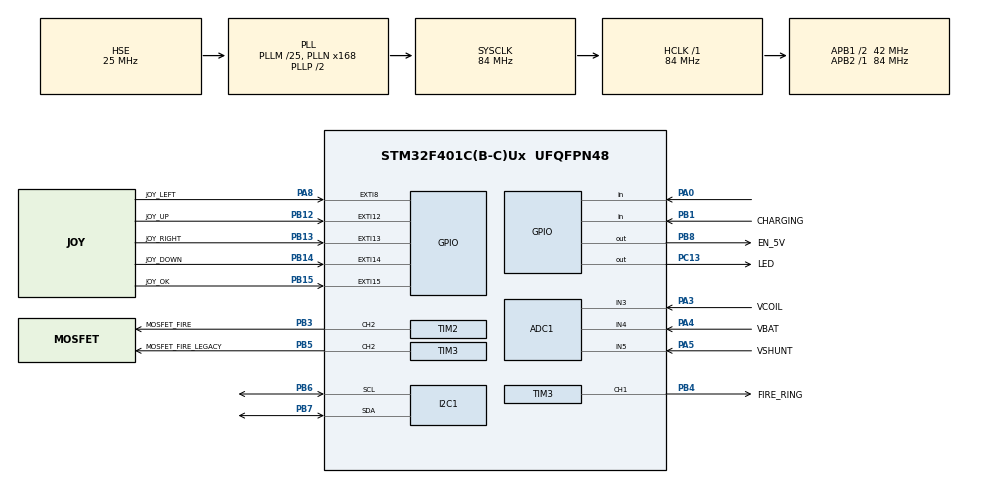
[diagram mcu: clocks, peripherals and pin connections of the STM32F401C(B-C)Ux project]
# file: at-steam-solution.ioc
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ADC1.Channel-0\#ChannelRegularConversion=ADC_CHANNEL_3
ADC1.Channel-1\#ChannelRegularConversion=ADC_CHANNEL_4
ADC1.Channel-2\#ChannelRegularConversion=ADC_CHANNEL_5
ADC1.ContinuousConvMode=ENABLE
ADC1.DMAContinuousRequests=ENABLE
ADC1.NbrOfConversion=3
ADC1.NbrOfConversionFlag=1
ADC1.Rank-0\#ChannelRegularConversion=1
ADC1.Rank-1\#ChannelRegularConversion=2
ADC1.Rank-2\#ChannelRegularConversion=3
ADC1.SamplingTime-0\#ChannelRegularConversion=ADC_SAMPLETIME_480CYCLES
ADC1.SamplingTime-1\#ChannelRegularConversion=ADC_SAMPLETIME_480CYCLES
ADC1.SamplingTime-2\#ChannelRegularConversion=ADC_SAMPLETIME_480CYCLES
ADC1.master=1
Dma.ADC1.0.Direction=DMA_PERIPH_TO_MEMORY
Dma.ADC1.0.FIFOMode=DMA_FIFOMODE_DISABLE
Dma.ADC1.0.Instance=DMA2_Stream0
Dma.ADC1.0.MemDataAlignment=DMA_MDATAALIGN_WORD
Dma.ADC1.0.MemInc=DMA_MINC_ENABLE
Dma.ADC1.0.Mode=DMA_CIRCULAR
Dma.ADC1.0.PeriphDataAlignment=DMA_PDATAALIGN_WORD
Dma.ADC1.0.PeriphInc=DMA_PINC_DISABLE
Dma.ADC1.0.Priority=DMA_PRIORITY_LOW
Dma.Request0=ADC1
I2C1.I2C_Mode=I2C_Fast
Mcu.Family=STM32F4
Mcu.Name=STM32F401C(B-C)Ux
Mcu.Package=UFQFPN48
NVIC.DMA2_Stream0_IRQn=true\:0\:0\:false\:false\:true\:false\:true
NVIC.EXTI15_10_IRQn=true\:0\:0\:false\:false\:true\:true\:true
NVIC.EXTI9_5_IRQn=true\:0\:0\:false\:false\:true\:true\:true
NVIC.PriorityGroup=NVIC_PRIORITYGROUP_4
NVIC.TIM4_IRQn=true\:0\:0\:false\:false\:true\:true\:true
PA0-WKUP.GPIO_PuPd=GPIO_PULLDOWN
PA0-WKUP.Signal=GPIO_Input
PA3.GPIO_Label=VCOIL
PA3.Signal=ADCx_IN3
PA4.GPIO_Label=VBAT
PA4.Signal=ADCx_IN4
PA5.GPIO_Label=VSHUNT
PA5.Signal=ADCx_IN5
PA8.GPIO_Label=JOY_LEFT
PA8.GPIO_ModeDefaultEXTI=GPIO_MODE_IT_RISING_FALLING
PA8.GPIO_PuPd=GPIO_PULLUP
PA8.Signal=GPXTI8
PB1.GPIO_Label=CHARGING
PB1.Signal=GPIO_Input
PB12.GPIO_Label=JOY_UP
PB12.GPIO_ModeDefaultEXTI=GPIO_MODE_IT_RISING_FALLING
PB12.GPIO_PuPd=GPIO_PULLUP
PB12.Signal=GPXTI12
PB13.GPIO_Label=JOY_RIGHT
PB13.GPIO_ModeDefaultEXTI=GPIO_MODE_IT_RISING_FALLING
PB13.GPIO_PuPd=GPIO_PULLUP
PB13.Signal=GPXTI13
PB14.GPIO_Label=JOY_DOWN
PB14.GPIO_ModeDefaultEXTI=GPIO_MODE_IT_RISING_FALLING
PB14.GPIO_PuPd=GPIO_PULLUP
PB14.Signal=GPXTI14
PB15.GPIO_Label=JOY_OK
PB15.GPIO_ModeDefaultEXTI=GPIO_MODE_IT_RISING_FALLING
PB15.GPIO_PuPd=GPIO_PULLUP
PB15.Signal=GPXTI15
PB3.GPIO_Label=MOSFET_FIRE
PB3.GPIO_ModeDefaultPP=GPIO_MODE_AF_OD
PB3.GPIO_Speed=GPIO_SPEED_FREQ_VERY_HIGH
PB3.Signal=S_TIM2_CH2
PB4.GPIO_Label=FIRE_RING
PB4.GPIO_ModeDefaultPP=GPIO_MODE_AF_OD
PB4.GPIO_Speed=GPIO_SPEED_FREQ_VERY_HIGH
PB4.Signal=S_TIM3_CH1
PB5.GPIO_Label=MOSFET_FIRE_LEGACY
PB5.GPIO_ModeDefaultPP=GPIO_MODE_AF_OD
PB5.GPIO_Speed=GPIO_SPEED_FREQ_VERY_HIGH
PB5.Signal=S_TIM3_CH2
PB6.GPIO_Pu=GPIO_PULLUP
PB6.Mode=I2C
PB6.Signal=I2C1_SCL
PB7.GPIO_Pu=GPIO_PULLUP
PB7.Mode=I2C
PB7.Signal=I2C1_SDA
PB8.GPIO_Label=EN_5V
PB8.Signal=GPIO_Output
PC13-ANTI_TAMP.GPIO_Label=LED
PC13-ANTI_TAMP.Signal=GPIO_Output
PC14-OSC32_IN.Mode=LSE-External-Oscillator
PC14-OSC32_IN.Signal=RCC_OSC32_IN
PC15-OSC32_OUT.Mode=LSE-External-Oscillator
PC15-OSC32_OUT.Signal=RCC_OSC32_OUT
PH0\ -\ OSC_IN.Mode=HSE-External-Oscillator
PH0\ -\ OSC_IN.Signal=RCC_OSC_IN
PH1\ -\ OSC_OUT.Mode=HSE-External-Oscillator
PH1\ -\ OSC_OUT.Signal=RCC_OSC_OUT
ProjectManager.HeapSize=0x200
ProjectManager.StackSize=0x400
ProjectManager.TargetToolchain=SW4STM32
RCC.48MHZClocksFreq_Value=42000000
RCC.AHBFreq_Value=84000000
RCC.APB1CLKDivider=RCC_HCLK_DIV2
RCC.APB1Freq_Value=42000000
RCC.APB1TimFreq_Value=84000000
RCC.APB2Freq_Value=84000000
RCC.APB2TimFreq_Value=84000000
RCC.CortexFreq_Value=84000000
RCC.HCLKFreq_Value=84000000
RCC.HSE_VALUE=25000000
RCC.HSI_VALUE=16000000
RCC.PLLM=25
RCC.PLLN=168
RCC.PLLSourceVirtual=RCC_PLLSOURCE_HSE
RCC.RCC_RTC_Clock_Source=RCC_RTCCLKSOURCE_LSE
RCC.RCC_RTC_Clock_SourceVirtual=RCC_RTCCLKSOURCE_LSE
RCC.RCC_RTC_Clock_Source_FROM_HSE=RCC_RTCCLKSOURCE_HSE_DIV25
RCC.SYSCLKFreq_VALUE=84000000
RCC.SYSCLKSource=RCC_SYSCLKSOURCE_PLLCLK
RCC.VCOOutputFreq_Value=168000000
RTC.AsynchPrediv=127
RTC.SynchPrediv=255
SH.ADCx_IN3.0=ADC1_IN3,IN3
SH.ADCx_IN4.0=ADC1_IN4,IN4
SH.ADCx_IN5.0=ADC1_IN5,IN5
SH.S_TIM2_CH2.0=TIM2_CH2,PWM Generation2 CH2
SH.S_TIM3_CH1.0=TIM3_CH1,PWM Generation1 CH1
SH.S_TIM3_CH2.0=TIM3_CH2,PWM Generation2 CH2
TIM2.Channel-PWM\ Generation2\ CH2=TIM_CHANNEL_2
TIM2.Period=10000-1
TIM2.Prescaler=100-1
TIM3.Channel-PWM\ Generation1\ CH1=TIM_CHANNEL_1
TIM3.Channel-PWM\ Generation2\ CH2=TIM_CHANNEL_2
TIM3.Period=10000-1
TIM3.Prescaler=100-1
TIM4.Period=8400-1
TIM4.Prescaler=100-1
VP_CRC_VS_CRC.Mode=CRC_Activate
VP_RTC_VS_RTC_Activate.Mode=RTC_Enabled
VP_RTC_VS_RTC_Calendar.Mode=RTC_Calendar
VP_TIM4_VS_ClockSourceINT.Mode=Internal
board=custom

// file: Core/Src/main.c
/* USER CODE BEGIN Header */
/*
 * Copyright (c) Alex2772, https://github.com/alex2772
 *
 * This program is free software: you can redistribute it and/or modify
 * it under the terms of the GNU General Public License as published by
 * the Free Software Foundation, either version 3 of the License, or
 * (at your option) any later version.
 *
 * This program is distributed in the hope that it will be useful,
 * but WITHOUT ANY WARRANTY; without even the implied warranty of
 * MERCHANTABILITY or FITNESS FOR A PARTICULAR PURPOSE.  See the
 * GNU General Public License for more details.
 *
 * You should have received a copy of the GNU General Public License
 * along with this program.  If not, see <http://www.gnu.org/licenses/>.
 */

/* USER CODE END Header */
#include "main.h"

ADC_HandleTypeDef hadc1;
DMA_HandleTypeDef hdma_adc1;

CRC_HandleTypeDef hcrc;

I2C_HandleTypeDef hi2c1;

RTC_HandleTypeDef hrtc;

TIM_HandleTypeDef htim2;
TIM_HandleTypeDef htim3;
TIM_HandleTypeDef htim4;

void SystemClock_Config(void);
static void MX_GPIO_Init(void);
static void MX_I2C1_Init(void);
static void MX_TIM3_Init(void);
static void MX_DMA_Init(void);
static void MX_ADC1_Init(void);
static void MX_TIM4_Init(void);
static void MX_CRC_Init(void);
static void MX_RTC_Init(void);
static void MX_TIM2_Init(void);

/* USER CODE BEGIN 0 */

extern void app_run();
/* USER CODE END 0 */

int main(void)
{

  /* MCU Configuration--------------------------------------------------------*/

  /* Reset of all peripherals, Initializes the Flash interface and the Systick. */
  HAL_Init();

  /* Configure the system clock */
  SystemClock_Config();

  /* Initialize all configured peripherals */
  MX_GPIO_Init();
  MX_I2C1_Init();
  MX_TIM3_Init();
  MX_DMA_Init();
  MX_ADC1_Init();
  MX_TIM4_Init();
  MX_CRC_Init();
  MX_RTC_Init();
  MX_TIM2_Init();
  /* USER CODE BEGIN 2 */

  HAL_PWR_EnableBkUpAccess();

  /* USER CODE END 2 */

  /* Infinite loop */
  while (1)
  {

    /* USER CODE BEGIN 3 */
    app_run();
  }
  /* USER CODE END 3 */
}

void SystemClock_Config(void)
{
  RCC_OscInitTypeDef RCC_OscInitStruct = {0};
  RCC_ClkInitTypeDef RCC_ClkInitStruct = {0};

  /** Configure the main internal regulator output voltage
  */
  __HAL_RCC_PWR_CLK_ENABLE();
  __HAL_PWR_VOLTAGESCALING_CONFIG(PWR_REGULATOR_VOLTAGE_SCALE2);
  /** Initializes the RCC Oscillators according to the specified parameters
  * in the RCC_OscInitTypeDef structure.
  */
  RCC_OscInitStruct.OscillatorType = RCC_OSCILLATORTYPE_HSE|RCC_OSCILLATORTYPE_LSE;
  RCC_OscInitStruct.HSEState = RCC_HSE_ON;
  RCC_OscInitStruct.LSEState = RCC_LSE_ON;
  RCC_OscInitStruct.PLL.PLLState = RCC_PLL_ON;
  RCC_OscInitStruct.PLL.PLLSource = RCC_PLLSOURCE_HSE;
  RCC_OscInitStruct.PLL.PLLM = 25;
  RCC_OscInitStruct.PLL.PLLN = 168;
  RCC_OscInitStruct.PLL.PLLP = RCC_PLLP_DIV2;
  RCC_OscInitStruct.PLL.PLLQ = 4;
  if (HAL_RCC_OscConfig(&RCC_OscInitStruct) != HAL_OK)
  {
    Error_Handler();
  }
  /** Initializes the CPU, AHB and APB buses clocks
  */
  RCC_ClkInitStruct.ClockType = RCC_CLOCKTYPE_HCLK|RCC_CLOCKTYPE_SYSCLK
                              |RCC_CLOCKTYPE_PCLK1|RCC_CLOCKTYPE_PCLK2;
  RCC_ClkInitStruct.SYSCLKSource = RCC_SYSCLKSOURCE_PLLCLK;
  RCC_ClkInitStruct.AHBCLKDivider = RCC_SYSCLK_DIV1;
  RCC_ClkInitStruct.APB1CLKDivider = RCC_HCLK_DIV2;
  RCC_ClkInitStruct.APB2CLKDivider = RCC_HCLK_DIV1;

  if (HAL_RCC_ClockConfig(&RCC_ClkInitStruct, FLASH_LATENCY_2) != HAL_OK)
  {
    Error_Handler();
  }
}

static void MX_ADC1_Init(void)
{

  ADC_ChannelConfTypeDef sConfig = {0};

  /** Configure the global features of the ADC (Clock, Resolution, Data Alignment and number of conversion)
  */
  hadc1.Instance = ADC1;
  hadc1.Init.ClockPrescaler = ADC_CLOCK_SYNC_PCLK_DIV4;
  hadc1.Init.Resolution = ADC_RESOLUTION_12B;
  hadc1.Init.ScanConvMode = ENABLE;
  hadc1.Init.ContinuousConvMode = ENABLE;
  hadc1.Init.DiscontinuousConvMode = DISABLE;
  hadc1.Init.ExternalTrigConvEdge = ADC_EXTERNALTRIGCONVEDGE_NONE;
  hadc1.Init.ExternalTrigConv = ADC_SOFTWARE_START;
  hadc1.Init.DataAlign = ADC_DATAALIGN_RIGHT;
  hadc1.Init.NbrOfConversion = 3;
  hadc1.Init.DMAContinuousRequests = ENABLE;
  hadc1.Init.EOCSelection = ADC_EOC_SINGLE_CONV;
  if (HAL_ADC_Init(&hadc1) != HAL_OK)
  {
    Error_Handler();
  }
  /** Configure for the selected ADC regular channel its corresponding rank in the sequencer and its sample time.
  */
  sConfig.Channel = ADC_CHANNEL_3;
  sConfig.Rank = 1;
  sConfig.SamplingTime = ADC_SAMPLETIME_480CYCLES;
  if (HAL_ADC_ConfigChannel(&hadc1, &sConfig) != HAL_OK)
  {
    Error_Handler();
  }
  /** Configure for the selected ADC regular channel its corresponding rank in the sequencer and its sample time.
  */
  sConfig.Channel = ADC_CHANNEL_4;
  sConfig.Rank = 2;
  if (HAL_ADC_ConfigChannel(&hadc1, &sConfig) != HAL_OK)
  {
    Error_Handler();
  }
  /** Configure for the selected ADC regular channel its corresponding rank in the sequencer and its sample time.
  */
  sConfig.Channel = ADC_CHANNEL_5;
  sConfig.Rank = 3;
  if (HAL_ADC_ConfigChannel(&hadc1, &sConfig) != HAL_OK)
  {
    Error_Handler();
  }

}

static void MX_CRC_Init(void)
{

  hcrc.Instance = CRC;
  if (HAL_CRC_Init(&hcrc) != HAL_OK)
  {
    Error_Handler();
  }

}

static void MX_I2C1_Init(void)
{

  hi2c1.Instance = I2C1;
  hi2c1.Init.ClockSpeed = 400000;
  hi2c1.Init.DutyCycle = I2C_DUTYCYCLE_2;
  hi2c1.Init.OwnAddress1 = 0;
  hi2c1.Init.AddressingMode = I2C_ADDRESSINGMODE_7BIT;
  hi2c1.Init.DualAddressMode = I2C_DUALADDRESS_DISABLE;
  hi2c1.Init.OwnAddress2 = 0;
  hi2c1.Init.GeneralCallMode = I2C_GENERALCALL_DISABLE;
  hi2c1.Init.NoStretchMode = I2C_NOSTRETCH_DISABLE;
  if (HAL_I2C_Init(&hi2c1) != HAL_OK)
  {
    Error_Handler();
  }

}

static void MX_RTC_Init(void)
{

  RTC_TimeTypeDef sTime = {0};
  RTC_DateTypeDef sDate = {0};

  /** Initialize RTC Only
  */
  hrtc.Instance = RTC;
  hrtc.Init.HourFormat = RTC_HOURFORMAT_24;
  hrtc.Init.AsynchPrediv = 127;
  hrtc.Init.SynchPrediv = 255;
  hrtc.Init.OutPut = RTC_OUTPUT_DISABLE;
  hrtc.Init.OutPutPolarity = RTC_OUTPUT_POLARITY_HIGH;
  hrtc.Init.OutPutType = RTC_OUTPUT_TYPE_OPENDRAIN;
  if (HAL_RTC_Init(&hrtc) != HAL_OK)
  {
    Error_Handler();
  }

  /* USER CODE BEGIN Check_RTC_BKUP */

  return;
  /* USER CODE END Check_RTC_BKUP */

  /** Initialize RTC and set the Time and Date
  */
  sTime.Hours = 0x0;
  sTime.Minutes = 0x0;
  sTime.Seconds = 0x0;
  sTime.DayLightSaving = RTC_DAYLIGHTSAVING_NONE;
  sTime.StoreOperation = RTC_STOREOPERATION_RESET;
  if (HAL_RTC_SetTime(&hrtc, &sTime, RTC_FORMAT_BCD) != HAL_OK)
  {
    Error_Handler();
  }
  sDate.WeekDay = RTC_WEEKDAY_MONDAY;
  sDate.Month = RTC_MONTH_JANUARY;
  sDate.Date = 0x1;
  sDate.Year = 0x0;

  if (HAL_RTC_SetDate(&hrtc, &sDate, RTC_FORMAT_BCD) != HAL_OK)
  {
    Error_Handler();
  }

}

static void MX_TIM2_Init(void)
{

  TIM_MasterConfigTypeDef sMasterConfig = {0};
  TIM_OC_InitTypeDef sConfigOC = {0};

  htim2.Instance = TIM2;
  htim2.Init.Prescaler = 100-1;
  htim2.Init.CounterMode = TIM_COUNTERMODE_UP;
  htim2.Init.Period = 10000-1;
  htim2.Init.ClockDivision = TIM_CLOCKDIVISION_DIV1;
  htim2.Init.AutoReloadPreload = TIM_AUTORELOAD_PRELOAD_DISABLE;
  if (HAL_TIM_PWM_Init(&htim2) != HAL_OK)
  {
    Error_Handler();
  }
  sMasterConfig.MasterOutputTrigger = TIM_TRGO_RESET;
  sMasterConfig.MasterSlaveMode = TIM_MASTERSLAVEMODE_DISABLE;
  if (HAL_TIMEx_MasterConfigSynchronization(&htim2, &sMasterConfig) != HAL_OK)
  {
    Error_Handler();
  }
  sConfigOC.OCMode = TIM_OCMODE_PWM1;
  sConfigOC.Pulse = 0;
  sConfigOC.OCPolarity = TIM_OCPOLARITY_HIGH;
  sConfigOC.OCFastMode = TIM_OCFAST_DISABLE;
  if (HAL_TIM_PWM_ConfigChannel(&htim2, &sConfigOC, TIM_CHANNEL_2) != HAL_OK)
  {
    Error_Handler();
  }
  HAL_TIM_MspPostInit(&htim2);

}

static void MX_TIM3_Init(void)
{

  TIM_MasterConfigTypeDef sMasterConfig = {0};
  TIM_OC_InitTypeDef sConfigOC = {0};

  htim3.Instance = TIM3;
  htim3.Init.Prescaler = 100-1;
  htim3.Init.CounterMode = TIM_COUNTERMODE_UP;
  htim3.Init.Period = 10000-1;
  htim3.Init.ClockDivision = TIM_CLOCKDIVISION_DIV1;
  htim3.Init.AutoReloadPreload = TIM_AUTORELOAD_PRELOAD_DISABLE;
  if (HAL_TIM_PWM_Init(&htim3) != HAL_OK)
  {
    Error_Handler();
  }
  sMasterConfig.MasterOutputTrigger = TIM_TRGO_RESET;
  sMasterConfig.MasterSlaveMode = TIM_MASTERSLAVEMODE_DISABLE;
  if (HAL_TIMEx_MasterConfigSynchronization(&htim3, &sMasterConfig) != HAL_OK)
  {
    Error_Handler();
  }
  sConfigOC.OCMode = TIM_OCMODE_PWM1;
  sConfigOC.Pulse = 0;
  sConfigOC.OCPolarity = TIM_OCPOLARITY_HIGH;
  sConfigOC.OCFastMode = TIM_OCFAST_DISABLE;
  if (HAL_TIM_PWM_ConfigChannel(&htim3, &sConfigOC, TIM_CHANNEL_1) != HAL_OK)
  {
    Error_Handler();
  }
  if (HAL_TIM_PWM_ConfigChannel(&htim3, &sConfigOC, TIM_CHANNEL_2) != HAL_OK)
  {
    Error_Handler();
  }
  HAL_TIM_MspPostInit(&htim3);

}

static void MX_TIM4_Init(void)
{

  TIM_ClockConfigTypeDef sClockSourceConfig = {0};
  TIM_MasterConfigTypeDef sMasterConfig = {0};

  htim4.Instance = TIM4;
  htim4.Init.Prescaler = 100-1;
  htim4.Init.CounterMode = TIM_COUNTERMODE_UP;
  htim4.Init.Period = 8400-1;
  htim4.Init.ClockDivision = TIM_CLOCKDIVISION_DIV1;
  htim4.Init.AutoReloadPreload = TIM_AUTORELOAD_PRELOAD_DISABLE;
  if (HAL_TIM_Base_Init(&htim4) != HAL_OK)
  {
    Error_Handler();
  }
  sClockSourceConfig.ClockSource = TIM_CLOCKSOURCE_INTERNAL;
  if (HAL_TIM_ConfigClockSource(&htim4, &sClockSourceConfig) != HAL_OK)
  {
    Error_Handler();
  }
  sMasterConfig.MasterOutputTrigger = TIM_TRGO_RESET;
  sMasterConfig.MasterSlaveMode = TIM_MASTERSLAVEMODE_DISABLE;
  if (HAL_TIMEx_MasterConfigSynchronization(&htim4, &sMasterConfig) != HAL_OK)
  {
    Error_Handler();
  }

}

static void MX_DMA_Init(void)
{

  /* DMA controller clock enable */
  __HAL_RCC_DMA2_CLK_ENABLE();

  /* DMA interrupt init */
  /* DMA2_Stream0_IRQn interrupt configuration */
  HAL_NVIC_SetPriority(DMA2_Stream0_IRQn, 0, 0);
  HAL_NVIC_EnableIRQ(DMA2_Stream0_IRQn);

}

static void MX_GPIO_Init(void)
{
  GPIO_InitTypeDef GPIO_InitStruct = {0};

  /* GPIO Ports Clock Enable */
  __HAL_RCC_GPIOC_CLK_ENABLE();
  __HAL_RCC_GPIOH_CLK_ENABLE();
  __HAL_RCC_GPIOA_CLK_ENABLE();
  __HAL_RCC_GPIOB_CLK_ENABLE();

  /*Configure GPIO pin Output Level */
  HAL_GPIO_WritePin(LED_GPIO_Port, LED_Pin, GPIO_PIN_RESET);

  /*Configure GPIO pin Output Level */
  HAL_GPIO_WritePin(EN_5V_GPIO_Port, EN_5V_Pin, GPIO_PIN_RESET);

  /*Configure GPIO pin : LED_Pin */
  GPIO_InitStruct.Pin = LED_Pin;
  GPIO_InitStruct.Mode = GPIO_MODE_OUTPUT_PP;
  GPIO_InitStruct.Pull = GPIO_NOPULL;
  GPIO_InitStruct.Speed = GPIO_SPEED_FREQ_LOW;
  HAL_GPIO_Init(LED_GPIO_Port, &GPIO_InitStruct);

  /*Configure GPIO pin : PA0 */
  GPIO_InitStruct.Pin = GPIO_PIN_0;
  GPIO_InitStruct.Mode = GPIO_MODE_INPUT;
  GPIO_InitStruct.Pull = GPIO_PULLDOWN;
  HAL_GPIO_Init(GPIOA, &GPIO_InitStruct);

  /*Configure GPIO pin : CHARGING_Pin */
  GPIO_InitStruct.Pin = CHARGING_Pin;
  GPIO_InitStruct.Mode = GPIO_MODE_INPUT;
  GPIO_InitStruct.Pull = GPIO_NOPULL;
  HAL_GPIO_Init(CHARGING_GPIO_Port, &GPIO_InitStruct);

  /*Configure GPIO pins : JOY_UP_Pin JOY_RIGHT_Pin JOY_DOWN_Pin JOY_OK_Pin */
  GPIO_InitStruct.Pin = JOY_UP_Pin|JOY_RIGHT_Pin|JOY_DOWN_Pin|JOY_OK_Pin;
  GPIO_InitStruct.Mode = GPIO_MODE_IT_RISING_FALLING;
  GPIO_InitStruct.Pull = GPIO_PULLUP;
  HAL_GPIO_Init(GPIOB, &GPIO_InitStruct);

  /*Configure GPIO pin : JOY_LEFT_Pin */
  GPIO_InitStruct.Pin = JOY_LEFT_Pin;
  GPIO_InitStruct.Mode = GPIO_MODE_IT_RISING_FALLING;
  GPIO_InitStruct.Pull = GPIO_PULLUP;
  HAL_GPIO_Init(JOY_LEFT_GPIO_Port, &GPIO_InitStruct);

  /*Configure GPIO pin : EN_5V_Pin */
  GPIO_InitStruct.Pin = EN_5V_Pin;
  GPIO_InitStruct.Mode = GPIO_MODE_OUTPUT_PP;
  GPIO_InitStruct.Pull = GPIO_NOPULL;
  GPIO_InitStruct.Speed = GPIO_SPEED_FREQ_LOW;
  HAL_GPIO_Init(EN_5V_GPIO_Port, &GPIO_InitStruct);

  /* EXTI interrupt init*/
  HAL_NVIC_SetPriority(EXTI9_5_IRQn, 0, 0);
  HAL_NVIC_EnableIRQ(EXTI9_5_IRQn);

  HAL_NVIC_SetPriority(EXTI15_10_IRQn, 0, 0);
  HAL_NVIC_EnableIRQ(EXTI15_10_IRQn);

}

void Error_Handler(void)
{
  /* USER CODE BEGIN Error_Handler_Debug */
  /* User can add his own implementation to report the HAL error return state */
  __disable_irq();
  while (1)
  {
      HAL_NVIC_SystemReset();
  }
  /* USER CODE END Error_Handler_Debug */
}

/************************ (C) COPYRIGHT STMicroelectronics *****END OF FILE****/
